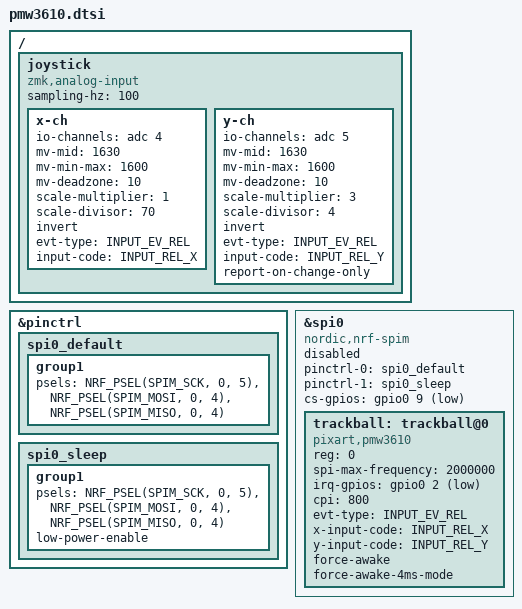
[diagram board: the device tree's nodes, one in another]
#include <zephyr/dt-bindings/input/input-event-codes.h>

&pinctrl {
    spi0_default: spi0_default {
        group1 {
            psels = <NRF_PSEL(SPIM_SCK, 0, 5)>,
                <NRF_PSEL(SPIM_MOSI, 0, 4)>,
                <NRF_PSEL(SPIM_MISO, 0, 4)>;
        };
    };

    spi0_sleep: spi0_sleep {
        group1 {
            psels = <NRF_PSEL(SPIM_SCK, 0, 5)>,
                <NRF_PSEL(SPIM_MOSI, 0, 4)>,
                <NRF_PSEL(SPIM_MISO, 0, 4)>;
            low-power-enable;
        };
    };
};

&spi0 {
    status = "disabled";
    compatible = "nordic,nrf-spim";
    pinctrl-0 = <&spi0_default>;
    pinctrl-1 = <&spi0_sleep>;
    pinctrl-names = "default", "sleep";
    cs-gpios = <&gpio0 9 GPIO_ACTIVE_LOW>;

    trackball: trackball@0 {
        status = "okay";
        compatible = "pixart,pmw3610";
        reg = <0>;
        spi-max-frequency = <2000000>;
        irq-gpios = <&gpio0 2 (GPIO_ACTIVE_LOW | GPIO_PULL_UP)>;
        cpi = <800>;
        evt-type = <INPUT_EV_REL>;
        x-input-code = <INPUT_REL_X>;
        y-input-code = <INPUT_REL_Y>;
        force-awake;
        force-awake-4ms-mode;
    };
};


/ {
	joystick: joystick {
		compatible = "zmk,analog-input";
		sampling-hz = <100>;
		x-ch {
			io-channels = <&adc 4>;
			mv-mid = <1630>;
			mv-min-max = <1600>;
			mv-deadzone = <10>;
			scale-multiplier = <1>;
			scale-divisor = <70>;
			invert;
			evt-type = <INPUT_EV_REL>;
			input-code = <INPUT_REL_X>;
		};
		y-ch {
			io-channels = <&adc 5>;
			mv-mid = <1630>;
			mv-min-max = <1600>;
			mv-deadzone = <10>;
			scale-multiplier = <3>;
			scale-divisor = <4>;
			invert;
			evt-type = <INPUT_EV_REL>;
			input-code = <INPUT_REL_Y>;

			/* enable report mdoe for gamepad axix or knob */
			/* to only call input_report on quantquantized value is updated */
			/* NOTE: mouse input does NOT need this */
			report-on-change-only;

		};
	};
};
